VERSION ""

BS_:

BU_:

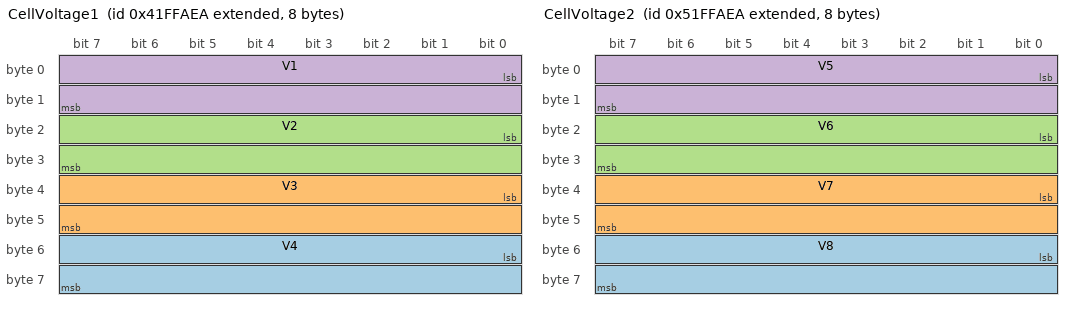
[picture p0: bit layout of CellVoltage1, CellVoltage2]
BO_ 2216688362 CellVoltage1: 8 Vector__XXX
 SG_ V4 : 48|16@1+ (1,0) [0|65535] "Volts" Vector__XXX
 SG_ V3 : 32|16@1+ (1,0) [0|65535] "Volts" Vector__XXX
 SG_ V2 : 16|16@1+ (1,0) [0|65535] "Volts" Vector__XXX
 SG_ V1 : 0|16@1+ (1,0) [0|65535] "Volts" Vector__XXX

BO_ 2233465578 CellVoltage2: 8 Vector__XXX
 SG_ V8 : 48|16@1+ (1,0) [0|65535] "Volts" Vector__XXX
 SG_ V7 : 32|16@1+ (1,0) [0|65535] "Volts" Vector__XXX
 SG_ V6 : 16|16@1+ (1,0) [0|65535] "Volts" Vector__XXX
 SG_ V5 : 0|16@1+ (1,0) [0|65535] "Volts" Vector__XXX

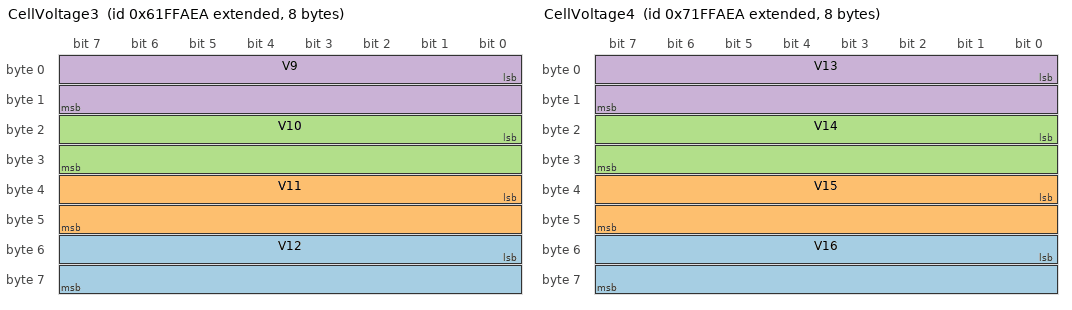
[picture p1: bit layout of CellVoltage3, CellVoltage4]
BO_ 2250242794 CellVoltage3: 8 Vector__XXX
 SG_ V12 : 48|16@1+ (1,0) [0|65535] "Volts" Vector__XXX
 SG_ V11 : 32|16@1+ (1,0) [0|65535] "Volts" Vector__XXX
 SG_ V10 : 16|16@1+ (1,0) [0|65535] "Volts" Vector__XXX
 SG_ V9 : 0|16@1+ (1,0) [0|65535] "Volts" Vector__XXX

BO_ 2267020010 CellVoltage4: 8 Vector__XXX
 SG_ V16 : 48|16@1+ (1,0) [0|65535] "Volts" Vector__XXX
 SG_ V15 : 32|16@1+ (1,0) [0|65535] "Volts" Vector__XXX
 SG_ V14 : 16|16@1+ (1,0) [0|65535] "Volts" Vector__XXX
 SG_ V13 : 0|16@1+ (1,0) [0|65535] "Volts" Vector__XXX

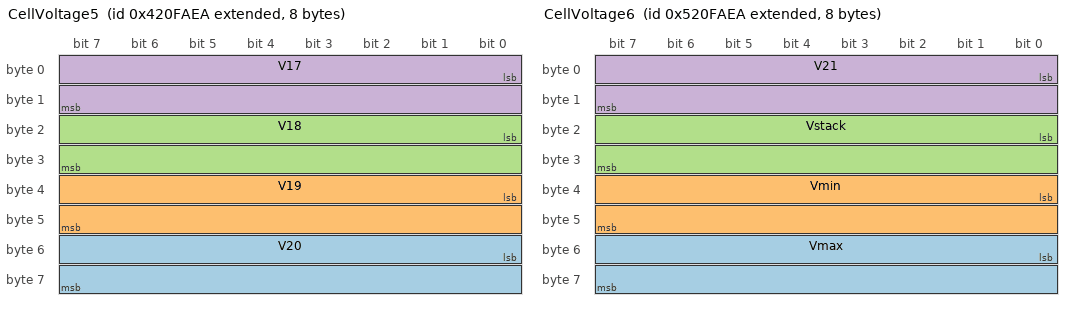
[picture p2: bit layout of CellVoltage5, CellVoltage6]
BO_ 2216753898 CellVoltage5: 8 Vector__XXX
 SG_ V20 : 48|16@1+ (1,0) [0|65535] "Volts" Vector__XXX
 SG_ V19 : 32|16@1+ (1,0) [0|65535] "Volts" Vector__XXX
 SG_ V18 : 16|16@1+ (1,0) [0|65535] "Volts" Vector__XXX
 SG_ V17 : 0|16@1+ (1,0) [0|65535] "Volts" Vector__XXX

BO_ 2233531114 CellVoltage6: 8 Vector__XXX
 SG_ Vmax : 48|16@1+ (1,0) [0|65535] "Volts" Vector__XXX
 SG_ Vmin : 32|16@1+ (1,0) [0|65535] "Volts" Vector__XXX
 SG_ Vstack : 16|16@1+ (1,0) [0|65535] "Volts" Vector__XXX
 SG_ V21 : 0|16@1+ (1,0) [0|65535] "Volts" Vector__XXX

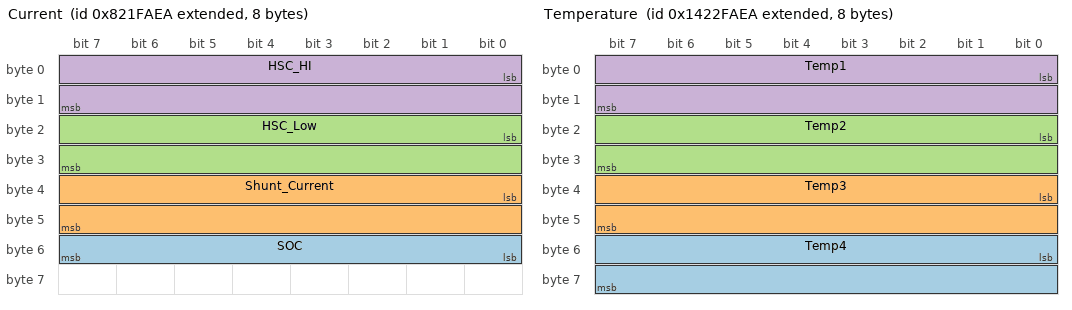
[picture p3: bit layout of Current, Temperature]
BO_ 2283928298 Current: 8 Vector__XXX
 SG_ SOC : 48|8@1+ (1,0) [0|255] "" Vector__XXX
 SG_ Shunt_Current : 32|16@1+ (1,0) [0|65535] "Amps" Vector__XXX
 SG_ HSC_Low : 16|16@1+ (1,0) [0|65535] "Amps" Vector__XXX
 SG_ HSC_HI : 0|16@1+ (1,0) [0|65535] "Amps" Vector__XXX

BO_ 2485320426 Temperature: 8 Vector__XXX
 SG_ Temp4 : 48|16@1+ (1,0) [0|65535] "DegC" Vector__XXX
 SG_ Temp3 : 32|16@1+ (1,0) [0|65535] "DegC" Vector__XXX
 SG_ Temp2 : 16|16@1+ (1,0) [0|65535] "DegC" Vector__XXX
 SG_ Temp1 : 0|16@1+ (1,0) [0|65535] "DegC" Vector__XXX

BO_ 2351168234 State: 8 Vector__XXX
 SG_ BalancingstatusC21 : 44|1@1- (1,0) [0|1] "" Vector__XXX
 SG_ BalancingstatusC20 : 43|1@1- (1,0) [0|1] "" Vector__XXX
 SG_ BalancingstatusC19 : 42|1@1- (1,0) [0|1] "" Vector__XXX
 SG_ BalancingstatusC18 : 41|1@1- (1,0) [0|1] "" Vector__XXX
 SG_ BalancingstatusC17 : 40|1@1- (1,0) [0|1] "" Vector__XXX
 SG_ BalancingstatusC16 : 39|1@1- (1,0) [0|1] "" Vector__XXX
 SG_ BalancingstatusC15 : 38|1@1- (1,0) [0|1] "" Vector__XXX
 SG_ BalancingstatusC14 : 37|1@1- (1,0) [0|1] "" Vector__XXX
 SG_ BalancingstatusC13 : 36|1@1- (1,0) [0|1] "" Vector__XXX
 SG_ BalancingstatusC12 : 35|1@1- (1,0) [0|1] "" Vector__XXX
 SG_ BalancingstatusC11 : 34|1@1- (1,0) [0|1] "" Vector__XXX
 SG_ BalancingstatusC10 : 33|1@1- (1,0) [0|1] "" Vector__XXX
 SG_ BalancingstatusC9 : 32|1@1- (1,0) [0|1] "" Vector__XXX
 SG_ BalancingstatusC8 : 31|1@1- (1,0) [0|1] "" Vector__XXX
 SG_ BalancingstatusC7 : 30|1@1- (1,0) [0|1] "" Vector__XXX
 SG_ BalancingstatusC6 : 29|1@1- (1,0) [0|1] "" Vector__XXX
 SG_ BalancingstatusC5 : 28|1@1- (1,0) [0|1] "" Vector__XXX
 SG_ BalancingstatusC4 : 27|1@1- (1,0) [0|1] "" Vector__XXX
 SG_ BalancingstatusC3 : 26|1@1- (1,0) [0|1] "" Vector__XXX
 SG_ BalancingstatusC2 : 25|1@1- (1,0) [0|1] "" Vector__XXX
 SG_ BalancingstatusC1 : 24|1@1- (1,0) [0|1] "" Vector__XXX
 SG_ VehicleState : 16|8@1+ (1,0) [0|255] "" Vector__XXX
 SG_ Ready : 7|1@1- (1,0) [0|1] "" Vector__XXX
 SG_ OverTemp : 4|1@1- (1,0) [0|1] "" Vector__XXX
 SG_ PrechargeFailure : 3|1@1- (1,0) [0|1] "" Vector__XXX
 SG_ OverCurrent : 2|1@1- (1,0) [0|1] "" Vector__XXX
 SG_ Undervoltage : 1|1@1- (1,0) [0|1] "" Vector__XXX
 SG_ OverVoltage : 0|1@1- (1,0) [0|1] "" Vector__XXX
